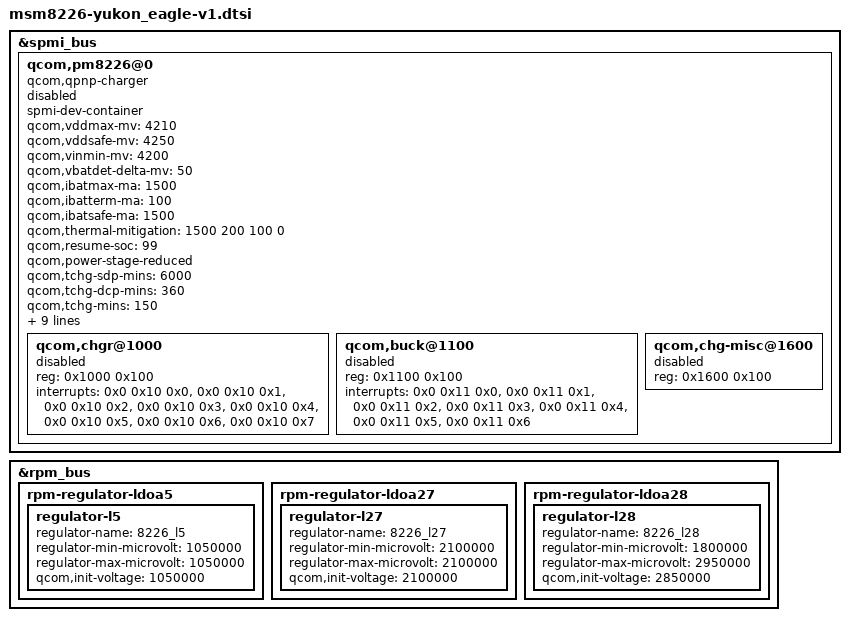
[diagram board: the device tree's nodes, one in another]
/include/ "msm8226-yukon_eagle-720p-mtp.dtsi"

&spmi_bus {
        qcom,pm8226@0 {
                        spmi-dev-container;
                        compatible = "qcom,qpnp-charger";
                        #address-cells = <1>;
                        #size-cells = <1>;
                        status = "disabled";
                        qcom,vddmax-mv = <4210>;
                        qcom,vddsafe-mv = <4250>;
                        qcom,vinmin-mv = <4200>;
                        qcom,vbatdet-delta-mv = <50>;
                        qcom,ibatmax-ma = <1500>;
                        qcom,ibatterm-ma = <100>;
                        qcom,ibatsafe-ma = <1500>;
                        qcom,thermal-mitigation = <1500 200 100 0>; //[Bug2690] S Jonny_Chan PSM
                        qcom,resume-soc = <99>;
                        qcom,power-stage-reduced; //[Bug1926] S Jonny_Chan 01435739
                        qcom,tchg-sdp-mins = <6000>;
                        qcom,tchg-dcp-mins = <360>;
                        qcom,tchg-mins = <150>;
                        qcom,chg-vadc = <&pm8226_vadc>;
                        qcom,chg-adc_tm = <&pm8226_adc_tm>;
                        qcom,pmic-revid = <&pm8226_revid>;
                        qcom,warm-bat-decidegc = <450>;
                        qcom,ibatmax-warm-ma = <400>;
                        qcom,warm-bat-mv = <4000>;
                        qcom,cool-bat-decidegc = <50>;
                        qcom,ibatmax-cool-ma = <0>;
                        qcom,cool-bat-mv = <4000>;
                        qcom,chgr@1000 {
                                status = "disabled";
                                reg = <0x1000 0x100>;
                                interrupts =    <0x0 0x10 0x0>,
                                                <0x0 0x10 0x1>,
                                                <0x0 0x10 0x2>,
                                                <0x0 0x10 0x3>,
                                                <0x0 0x10 0x4>,
                                                <0x0 0x10 0x5>,
                                                <0x0 0x10 0x6>,
                                                <0x0 0x10 0x7>;

                                interrupt-names =       "vbat-det-lo",
                                                        "vbat-det-hi",
                                                        "chgwdog",
                                                        "state-change",
                                                        "trkl-chg-on",
                                                        "fast-chg-on",
                                                        "chg-failed",
                                                        "chg-done";
                        };

                        qcom,buck@1100 {
                                status = "disabled";
                                reg = <0x1100 0x100>;
                                interrupts =    <0x0 0x11 0x0>,
                                                <0x0 0x11 0x1>,
                                                <0x0 0x11 0x2>,
                                                <0x0 0x11 0x3>,
                                                <0x0 0x11 0x4>,
                                                <0x0 0x11 0x5>,
                                                <0x0 0x11 0x6>;

                                interrupt-names =       "vbat-ov",
                                                        "vreg-ov",
                                                        "overtemp",
                                                        "vchg-loop",
                                                        "ichg-loop",
                                                        "ibat-loop",
                                                        "vdd-loop";
                        };

                        qcom,chg-misc@1600 {
                                status = "disabled";
                                reg = <0x1600 0x100>;
                        };
        };
};

&rpm_bus {
        rpm-regulator-ldoa5 {
                regulator-l5 {
                        regulator-name = "8226_l5";
                        regulator-min-microvolt = <1050000>;
                        regulator-max-microvolt = <1050000>;
                        qcom,init-voltage = <1050000>;
                        status = "okay";
                };
        };
        rpm-regulator-ldoa27 {
                regulator-l27 {
                        regulator-name = "8226_l27";
                        regulator-min-microvolt = <2100000>;
                        regulator-max-microvolt = <2100000>;
                        qcom,init-voltage = <2100000>;
                        status = "okay";
                };
        };
        rpm-regulator-ldoa28 {
                regulator-l28 {
                        regulator-name = "8226_l28";
                        regulator-min-microvolt = <1800000>;
                        regulator-max-microvolt = <2950000>;
                        qcom,init-voltage = <2850000>;
                        status = "okay";
                };
        };
};
